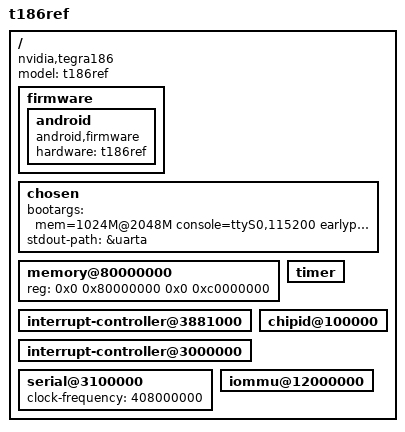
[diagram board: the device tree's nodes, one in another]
/*
 * arch/arm64/boot/dts/tegra194-sim-private.dts
 *
 * Copyright (c) 2016, NVIDIA CORPORATION.  All rights reserved.
 *
 * This program is free software; you can redistribute it and/or modify
 * it under the terms of the GNU General Public License as published by
 * the Free Software Foundation; version 2 of the License.
 *
 * This program is distributed in the hope that it will be useful, but WITHOUT
 * ANY WARRANTY; without even the implied warranty of MERCHANTABILITY or
 * FITNESS FOR A PARTICULAR PURPOSE.  See the GNU General Public License for
 * more details.
 *
 */

/dts-v1/;

/memreserve/ 0x80000000 0x00010000;

#include "tegra194-soc/tegra194-soc-base.dtsi"
#include "tegra194-soc/tegra194-cpus.dtsi"
/ {
	model = "t186ref";
	compatible = "nvidia,tegra186";

	firmware {
		android {
			compatible = "android,firmware";
			hardware = "t186ref";
		};
	};

	chosen {
		bootargs ="mem=1024M@2048M console=ttyS0,115200 earlyprintk=uart8250-32bit,0x03100000";
		stdout-path = &uarta;
	};

	memory@80000000 {
		device_type = "memory";
		reg = < 0x0 0x80000000 0x0 0xc0000000 >;
	};

	interrupt-controller@3881000 {
		status = "okay";
	};

	interrupt-controller@3000000 {
		status = "okay";
	};

	timer {
		status = "okay";
	};

	serial@3100000 {
		status = "okay";
		clock-frequency = <408000000>;
	};

	chipid@100000 {
		status = "okay";
	};

	iommu@12000000 {
		status = "okay";
	};
};
